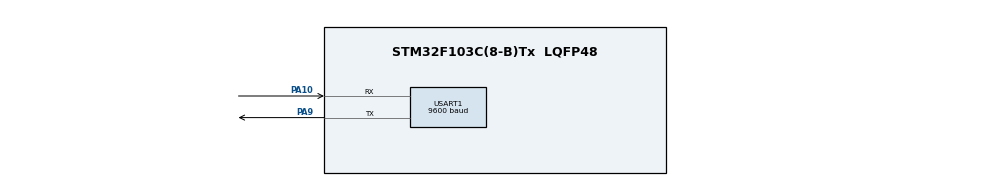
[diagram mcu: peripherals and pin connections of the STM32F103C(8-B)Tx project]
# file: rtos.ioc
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FREERTOS.Tasks01=defaultTask,24,128,StartDefaultTask,Default,NULL,Dynamic,NULL,NULL;myTask02,8,128,StartTask02,Default,NULL,Dynamic,NULL,NULL;myTask03,40,128,StartTask03,Default,NULL,Dynamic,NULL,NULL
FREERTOS.configUSE_NEWLIB_REENTRANT=1
Mcu.Family=STM32F1
Mcu.Name=STM32F103C(8-B)Tx
Mcu.Package=LQFP48
NVIC.PriorityGroup=NVIC_PRIORITYGROUP_4
NVIC.TIM1_UP_IRQn=true\:15\:0\:false\:false\:true\:false\:false\:true\:true
NVIC.TimeBase=TIM1_UP_IRQn
NVIC.TimeBaseIP=TIM1
PA10.Mode=Asynchronous
PA10.Signal=USART1_RX
PA13.Mode=Serial_Wire
PA13.Signal=SYS_JTMS-SWDIO
PA14.Mode=Serial_Wire
PA14.Signal=SYS_JTCK-SWCLK
PA9.Mode=Asynchronous
PA9.Signal=USART1_TX
ProjectManager.HeapSize=0x200
ProjectManager.StackSize=0x400
ProjectManager.TargetToolchain=MDK-ARM V5.32
RCC.APB1Freq_Value=8000000
RCC.APB2Freq_Value=8000000
RCC.APB2TimFreq_Value=8000000
USART1.BaudRate=9600
USART1.VirtualMode=VM_ASYNC
VP_FREERTOS_VS_CMSIS_V2.Mode=CMSIS_V2
VP_SYS_VS_tim1.Mode=TIM1
board=custom

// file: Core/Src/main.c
/* USER CODE BEGIN Header */
/**
  ******************************************************************************
  * @file           : main.c
  * @brief          : Main program body
  ******************************************************************************
  * @attention
  *
  * Copyright (c) 2025 STMicroelectronics.
  * All rights reserved.
  *
  * This software is licensed under terms that can be found in the LICENSE file
  * in the root directory of this software component.
  * If no LICENSE file comes with this software, it is provided AS-IS.
  *
  ******************************************************************************
  */
/* USER CODE END Header */
#include "main.h"
#include "cmsis_os.h"

UART_HandleTypeDef huart1;

/* Definitions for defaultTask */
osThreadId_t defaultTaskHandle;
const osThreadAttr_t defaultTask_attributes = {
  .name = "defaultTask",
  .stack_size = 128 * 4,
  .priority = (osPriority_t) osPriorityNormal,
};
/* Definitions for myTask02 */
osThreadId_t myTask02Handle;
const osThreadAttr_t myTask02_attributes = {
  .name = "myTask02",
  .stack_size = 128 * 4,
  .priority = (osPriority_t) osPriorityLow,
};
/* Definitions for myTask03 */
osThreadId_t myTask03Handle;
const osThreadAttr_t myTask03_attributes = {
  .name = "myTask03",
  .stack_size = 128 * 4,
  .priority = (osPriority_t) osPriorityHigh,
};

void SystemClock_Config(void);
static void MX_GPIO_Init(void);
static void MX_USART1_UART_Init(void);
void StartDefaultTask(void *argument);
void StartTask02(void *argument);
void StartTask03(void *argument);

int main(void)
{

  /* MCU Configuration--------------------------------------------------------*/

  /* Reset of all peripherals, Initializes the Flash interface and the Systick. */
  HAL_Init();

  /* Configure the system clock */
  SystemClock_Config();

  /* Initialize all configured peripherals */
  MX_GPIO_Init();
  MX_USART1_UART_Init();

  /* Init scheduler */
  osKernelInitialize();

  /* Create the thread(s) */
  /* creation of defaultTask */
  defaultTaskHandle = osThreadNew(StartDefaultTask, NULL, &defaultTask_attributes);

  /* creation of myTask02 */
  myTask02Handle = osThreadNew(StartTask02, NULL, &myTask02_attributes);

  /* creation of myTask03 */
  myTask03Handle = osThreadNew(StartTask03, NULL, &myTask03_attributes);

  /* Start scheduler */
  osKernelStart();

  /* We should never get here as control is now taken by the scheduler */

  /* Infinite loop */
  while (1)
  {

  }
}

void SystemClock_Config(void)
{
  RCC_OscInitTypeDef RCC_OscInitStruct = {0};
  RCC_ClkInitTypeDef RCC_ClkInitStruct = {0};

  /** Initializes the RCC Oscillators according to the specified parameters
  * in the RCC_OscInitTypeDef structure.
  */
  RCC_OscInitStruct.OscillatorType = RCC_OSCILLATORTYPE_HSI;
  RCC_OscInitStruct.HSIState = RCC_HSI_ON;
  RCC_OscInitStruct.HSICalibrationValue = RCC_HSICALIBRATION_DEFAULT;
  RCC_OscInitStruct.PLL.PLLState = RCC_PLL_NONE;
  if (HAL_RCC_OscConfig(&RCC_OscInitStruct) != HAL_OK)
  {
    Error_Handler();
  }

  /** Initializes the CPU, AHB and APB buses clocks
  */
  RCC_ClkInitStruct.ClockType = RCC_CLOCKTYPE_HCLK|RCC_CLOCKTYPE_SYSCLK
                              |RCC_CLOCKTYPE_PCLK1|RCC_CLOCKTYPE_PCLK2;
  RCC_ClkInitStruct.SYSCLKSource = RCC_SYSCLKSOURCE_HSI;
  RCC_ClkInitStruct.AHBCLKDivider = RCC_SYSCLK_DIV1;
  RCC_ClkInitStruct.APB1CLKDivider = RCC_HCLK_DIV1;
  RCC_ClkInitStruct.APB2CLKDivider = RCC_HCLK_DIV1;

  if (HAL_RCC_ClockConfig(&RCC_ClkInitStruct, FLASH_LATENCY_0) != HAL_OK)
  {
    Error_Handler();
  }
}

static void MX_USART1_UART_Init(void)
{

  huart1.Instance = USART1;
  huart1.Init.BaudRate = 9600;
  huart1.Init.WordLength = UART_WORDLENGTH_8B;
  huart1.Init.StopBits = UART_STOPBITS_1;
  huart1.Init.Parity = UART_PARITY_NONE;
  huart1.Init.Mode = UART_MODE_TX_RX;
  huart1.Init.HwFlowCtl = UART_HWCONTROL_NONE;
  huart1.Init.OverSampling = UART_OVERSAMPLING_16;
  if (HAL_UART_Init(&huart1) != HAL_OK)
  {
    Error_Handler();
  }

}

static void MX_GPIO_Init(void)
{

  /* GPIO Ports Clock Enable */
  __HAL_RCC_GPIOA_CLK_ENABLE();

}

void StartDefaultTask(void *argument)
{
  /* USER CODE BEGIN 5 */
	const char *task1 = "Runing default task...\r\n";

  /* Infinite loop */
  for(;;)
  {
		HAL_UART_Transmit(&huart1, &task1, strlen(task1),HAL_MAX_DELAY);
    osDelay(100);
  }
  /* USER CODE END 5 */
}

void StartTask02(void *argument)
{
  /* USER CODE BEGIN StartTask02 */
	const char *task2 = "Runing task 2...\r\n";

  /* Infinite loop */
  for(;;)
  {
		HAL_UART_Transmit(&huart1, &task2, strlen(task2),HAL_MAX_DELAY);
    osDelay(100);
  }
  /* USER CODE END StartTask02 */
}

void StartTask03(void *argument)
{
  /* USER CODE BEGIN StartTask03 */
	const char *task3 = "Running task 3...\r\n";

  /* Infinite loop */
  for(;;)
  {
		HAL_UART_Transmit(&huart1,&task3,strlen(task3),HAL_MAX_DELAY);
    osDelay(100);
  }
  /* USER CODE END StartTask03 */
}

void HAL_TIM_PeriodElapsedCallback(TIM_HandleTypeDef *htim)
{
  if (htim->Instance == TIM1) {
    HAL_IncTick();
  }
}

void Error_Handler(void)
{
  __disable_irq();
  while (1)
  {
  }
}
